AUTOSAR XML (schema 314)
package /ComponentType
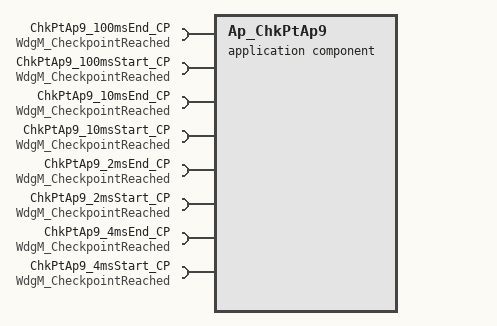
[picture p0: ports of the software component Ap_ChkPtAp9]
  application software component type Ap_ChkPtAp9
    8 x require port, all with client-com-spec=CheckpointReached, required-interface=WdgM_CheckpointReached:
      ChkPtAp9_100msEnd_CP
      ChkPtAp9_100msStart_CP
      ChkPtAp9_10msEnd_CP
      ChkPtAp9_10msStart_CP
      ChkPtAp9_2msEnd_CP
      ChkPtAp9_2msStart_CP
      ChkPtAp9_4msEnd_CP
      ChkPtAp9_4msStart_CP
  internal behavior Ap_ChkPtAp9_InternalBehavior: component=Ap_ChkPtAp9
    8 x timing event:
      TMT_ChkPtAp9_100msEnd_Per: start-on-event=ChkPtAp9_100msEnd_Per, period=0.1
      TMT_ChkPtAp9_100msStart_Per: start-on-event=ChkPtAp9_100msStart_Per, period=0.1
      TMT_ChkPtAp9_10msEnd_Per: start-on-event=ChkPtAp9_10msEnd_Per, period=0.01
      TMT_ChkPtAp9_10msStart_Per: start-on-event=ChkPtAp9_10msStart_Per, period=0.01
      TMT_ChkPtAp9_2msEnd_Per: start-on-event=ChkPtAp9_2msEnd_Per, period=0.002
      TMT_ChkPtAp9_2msStart_Per: start-on-event=ChkPtAp9_2msStart_Per, period=0.002
      TMT_ChkPtAp9_4msEnd_Per: start-on-event=ChkPtAp9_4msEnd_Per, period=0.004
      TMT_ChkPtAp9_4msStart_Per: start-on-event=ChkPtAp9_4msStart_Per, period=0.004
    port-api-options:
      enable-take-address=false, indirect-api=false, port=ChkPtAp9_100msEnd_CP
      enable-take-address=false, indirect-api=false, port=ChkPtAp9_100msStart_CP
      enable-take-address=false, indirect-api=false, port=ChkPtAp9_10msEnd_CP
      enable-take-address=false, indirect-api=false, port=ChkPtAp9_10msStart_CP
      enable-take-address=false, indirect-api=false, port=ChkPtAp9_2msEnd_CP
      enable-take-address=false, indirect-api=false, port=ChkPtAp9_2msStart_CP
      enable-take-address=false, indirect-api=false, port=ChkPtAp9_4msEnd_CP
      enable-take-address=false, indirect-api=false, port=ChkPtAp9_4msStart_CP
    8 x runnable:
      ChkPtAp9_100msEnd_Per
        sync call SC_ChkPtAp9_100msEnd_CP_CheckpointReached: operation=ChkPtAp9_100msEnd_CP.CheckpointReached, timeout=0
      ChkPtAp9_100msStart_Per
        sync call SC_ChkPtAp9_100msStart_CP_CheckpointReached: operation=ChkPtAp9_100msStart_CP.CheckpointReached, timeout=0
      ChkPtAp9_10msEnd_Per
        sync call SC_ChkPtAp9_10msEnd_CP_CheckpointReached: operation=ChkPtAp9_10msEnd_CP.CheckpointReached, timeout=0
      ChkPtAp9_10msStart_Per
        sync call SC_ChkPtAp9_10msStart_CP_CheckpointReached: operation=ChkPtAp9_10msStart_CP.CheckpointReached, timeout=0
      ChkPtAp9_2msEnd_Per
        sync call SC_ChkPtAp9_2msEnd_CP_CheckpointReached: operation=ChkPtAp9_2msEnd_CP.CheckpointReached, timeout=0
      ChkPtAp9_2msStart_Per
        sync call SC_ChkPtAp9_2msStart_CP_CheckpointReached: operation=ChkPtAp9_2msStart_CP.CheckpointReached, timeout=0
      ChkPtAp9_4msEnd_Per
        sync call SC_ChkPtAp9_4msEnd_CP_CheckpointReached: operation=ChkPtAp9_4msEnd_CP.CheckpointReached, timeout=0
      ChkPtAp9_4msStart_Per
        sync call SC_ChkPtAp9_4msStart_CP_CheckpointReached: operation=ChkPtAp9_4msStart_CP.CheckpointReached, timeout=0
  swc implementation Ap_ChkPtAp9_Implementation: behavior=Ap_ChkPtAp9_InternalBehavior
    code-descriptors:
      code Code: type=SRC
